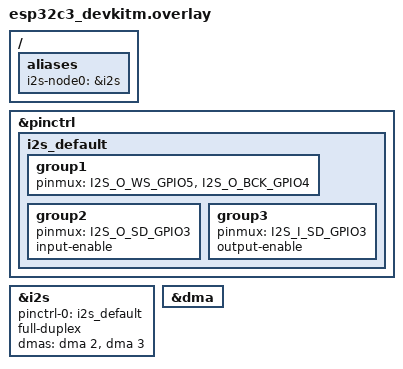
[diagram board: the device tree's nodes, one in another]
/*
 * Copyright (c) 2025 Espressif Systems (Shanghai) Co., Ltd.
 *
 * SPDX-License-Identifier: Apache-2.0
 */

/* i2s-node0 is the transmitter/receiver */

/ {
	aliases {
		i2s-node0 = &i2s;
	};
};

&pinctrl {
	i2s_default: i2s_default {
		group1 {
			pinmux = <I2S_O_WS_GPIO5>,
				 <I2S_O_BCK_GPIO4>;
		};

		group2 {
			pinmux =  <I2S_O_SD_GPIO3>;
			input-enable;
		};

		group3 {
			pinmux = <I2S_I_SD_GPIO3>;
			output-enable;
		};
	};
};

&i2s {
	status = "okay";
	pinctrl-0 = <&i2s_default>;
	pinctrl-names = "default";

	full-duplex;
	dmas = <&dma 2>, <&dma 3>;
	dma-names = "rx", "tx";
};

&dma {
	status = "okay";
};
